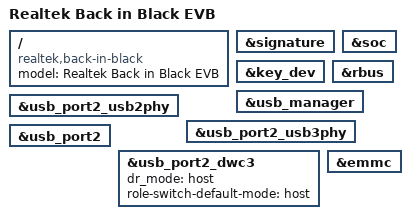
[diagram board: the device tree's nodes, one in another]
// SPDX-License-Identifier: (GPL-2.0-or-later OR BSD-2-Clause)
/*
 * Copyright (c) 2020 Realtek Semiconductor Corp.
 */

/dts-v1/;

#include "rtd1619b-backinblack.dtsi"

/ {
	compatible = "realtek,back-in-black", "realtek,rtd1619b";
	model = "Realtek Back in Black EVB";
};

&signature {
	bootph-all;
};

&key_dev {
	bootph-all;
};

&soc {
	bootph-all;
};

&rbus {
	bootph-all;
};

&usb_manager {
	bootph-all;
};

&usb_port2_usb2phy {
	bootph-all;
};

&usb_port2_usb3phy {
	bootph-all;
};

&usb_port2 {
	bootph-all;
};

&usb_port2_dwc3 {
	bootph-all;
	dr_mode = "host"; /* otg, host, peripheral*/
	role-switch-default-mode = "host"; /* host, peripheral */
};

&emmc {
	bootph-all;
};
